AUTOSAR XML (schema 4-2-2)
package /EB/SoftwareComponents
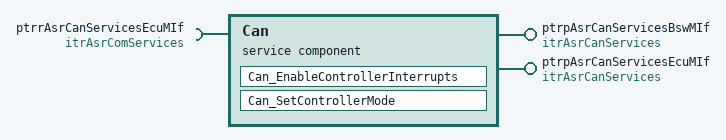
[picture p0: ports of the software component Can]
  service sw component type Can: category=ASR_Interfaces
    provide port ptrpAsrCanServicesBswMIf: provided-interface=itrAsrCanServices
    provide port ptrpAsrCanServicesEcuMIf: provided-interface=itrAsrCanServices
    require port ptrrAsrCanServicesEcuMIf: required-interface=itrAsrComServices
    behavior Can_IB: handle-termination-and-restart=NO-SUPPORT
      runnable Can_EnableControllerInterrupts
      runnable Can_SetControllerMode
package /EB/TriggerInterfaces
  trigger interface itrAsrCanServices
    4 x trigger, all with trigger-period={cse-code=1000, cse-code-factor=0}:
      Can_CheckWakeup
      Can_EnableControllerInterrupts
      Can_Init
      Can_SetControllerMode
